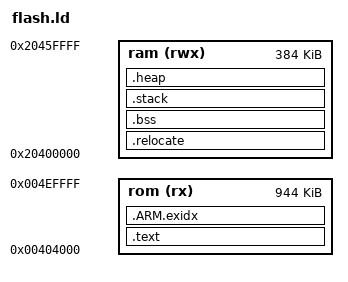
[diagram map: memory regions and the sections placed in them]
/**
 * \file
 *
 * Copyright (c) 2015 Microchip Technology Inc. All rights reserved.
 *
 * \asf_license_start
 *
 * \page License
 *
 * Redistribution and use in source and binary forms, with or without
 * modification, are permitted provided that the following conditions are met:
 *
 * 1. Redistributions of source code must retain the above copyright notice,
 *    this list of conditions and the following disclaimer.
 *
 * 2. Redistributions in binary form must reproduce the above copyright notice,
 *    this list of conditions and the following disclaimer in the documentation
 *    and/or other materials provided with the distribution.
 *
 * 3. The name of Atmel may not be used to endorse or promote products derived
 *    from this software without specific prior written permission.
 *
 * 4. This software may only be redistributed and used in connection with an
 *    Atmel microcontroller product.
 *
 * THIS SOFTWARE IS PROVIDED BY ATMEL "AS IS" AND ANY EXPRESS OR IMPLIED
 * WARRANTIES, INCLUDING, BUT NOT LIMITED TO, THE IMPLIED WARRANTIES OF
 * MERCHANTABILITY, FITNESS FOR A PARTICULAR PURPOSE AND NON-INFRINGEMENT ARE
 * EXPRESSLY AND SPECIFICALLY DISCLAIMED. IN NO EVENT SHALL ATMEL BE LIABLE FOR
 * ANY DIRECT, INDIRECT, INCIDENTAL, SPECIAL, EXEMPLARY, OR CONSEQUENTIAL
 * DAMAGES (INCLUDING, BUT NOT LIMITED TO, PROCUREMENT OF SUBSTITUTE GOODS
 * OR SERVICES; LOSS OF USE, DATA, OR PROFITS; OR BUSINESS INTERRUPTION)
 * HOWEVER CAUSED AND ON ANY THEORY OF LIABILITY, WHETHER IN CONTRACT,
 * STRICT LIABILITY, OR TORT (INCLUDING NEGLIGENCE OR OTHERWISE) ARISING IN
 * ANY WAY OUT OF THE USE OF THIS SOFTWARE, EVEN IF ADVISED OF THE
 * POSSIBILITY OF SUCH DAMAGE.
 *
 * \asf_license_stop
 *
 */

/*------------------------------------------------------------------------------
 *      Linker script for running in internal FLASH on the ATSAME70Q20
 *----------------------------------------------------------------------------*/

OUTPUT_FORMAT("elf32-littlearm", "elf32-littlearm", "elf32-littlearm")
OUTPUT_ARCH(arm)
SEARCH_DIR(.)

/* Memory Spaces Definitions */
MEMORY
{
  rom (rx)  : ORIGIN = 0x00404000, LENGTH = 0x000EC000
  ram (rwx) : ORIGIN = 0x20400000, LENGTH = 0x00060000
}

/* The stack size used by the application. NOTE: you need to adjust according to your application. */
STACK_SIZE = DEFINED(STACK_SIZE) ? STACK_SIZE : 0x2000;
__ram_end__ = ORIGIN(ram) + LENGTH(ram) - 4;

/* The heapsize used by the application. NOTE: you need to adjust according to your application. */
HEAP_SIZE = DEFINED(HEAP_SIZE) ? HEAP_SIZE : 0x400;

/* Section Definitions */
SECTIONS
{
    .text :
    {
        . = ALIGN(4);
        _sfixed = .;
        KEEP(*(.vectors .vectors.*))

		/* SIGNATURE */
		BYTE(0x45); BYTE(0x0F); BYTE(0xF9); BYTE(0xA7); BYTE(0x17); BYTE(0x7D); BYTE(0x4E); BYTE(0x99); BYTE(0xDB); BYTE(0x53); BYTE(0xA2); BYTE(0x72); BYTE(0xE7); BYTE(0xC3); BYTE(0xE1); BYTE(0x51);

		/* REPEAT SIGNATURE TO INDICATE EXTENDED INFO AVAILABLE */
		BYTE(0x45); BYTE(0x0F); BYTE(0xF9); BYTE(0xA7); BYTE(0x17); BYTE(0x7D); BYTE(0x4E); BYTE(0x99); BYTE(0xDB); BYTE(0x53); BYTE(0xA2); BYTE(0x72); BYTE(0xE7); BYTE(0xC3); BYTE(0xE1); BYTE(0x51);

		/*
		EXTENDED INFO - First four bytes are flags, followed by info
		Flag 0x00000001 : Version info bit. Version is 32 bit unsigned integer, little endian.
		*/
		BYTE(0x00); BYTE(0x00); BYTE(0x00); BYTE(0x01); BYTE(0x00); BYTE(0x00); BYTE(0x00); BYTE(0x01);

        *(.text .text.* .gnu.linkonce.t.*)
        *(.glue_7t) *(.glue_7)
        *(.rodata .rodata* .gnu.linkonce.r.*)
        *(.ARM.extab* .gnu.linkonce.armextab.*)

        /* Support C constructors, and C destructors in both user code
           and the C library. This also provides support for C++ code. */
        . = ALIGN(4);
        KEEP(*(.init))
        . = ALIGN(4);
        __preinit_array_start = .;
        KEEP (*(.preinit_array))
        __preinit_array_end = .;

        . = ALIGN(4);
        __init_array_start = .;
        KEEP (*(SORT(.init_array.*)))
        KEEP (*(.init_array))
        __init_array_end = .;

        . = ALIGN(0x4);
        KEEP (*crtbegin.o(.ctors))
        KEEP (*(EXCLUDE_FILE (*crtend.o) .ctors))
        KEEP (*(SORT(.ctors.*)))
        KEEP (*crtend.o(.ctors))

        . = ALIGN(4);
        KEEP(*(.fini))

        . = ALIGN(4);
        __fini_array_start = .;
        KEEP (*(.fini_array))
        KEEP (*(SORT(.fini_array.*)))
        __fini_array_end = .;

        KEEP (*crtbegin.o(.dtors))
        KEEP (*(EXCLUDE_FILE (*crtend.o) .dtors))
        KEEP (*(SORT(.dtors.*)))
        KEEP (*crtend.o(.dtors))

		KEEP(*(.WMMData))

        . = ALIGN(4);
        _efixed = .;            /* End of text section */
    } > rom

    /* .ARM.exidx is sorted, so has to go in its own output section.  */
    PROVIDE_HIDDEN (__exidx_start = .);
    .ARM.exidx :
    {
      *(.ARM.exidx* .gnu.linkonce.armexidx.*)
    } > rom
    PROVIDE_HIDDEN (__exidx_end = .);

    . = ALIGN(4);
    _etext = .;

    .relocate : AT (_etext)
    {
        . = ALIGN(4);
        _srelocate = .;
        *(.ramfunc .ramfunc.*);
        *(.data .data.*);
        . = ALIGN(4);
        _erelocate = .;
    } > ram

    /* .bss section which is used for uninitialized data */
    .bss (NOLOAD) :
    {
        . = ALIGN(4);
        _sbss = . ;
        _szero = .;
        *(.bss .bss.*)
        *(COMMON)
        . = ALIGN(4);
        _ebss = . ;
        _ezero = .;
    } > ram

    /* stack section */
    .stack (NOLOAD):
    {
        . = ALIGN(8);
        _sstack = .;
        . = . + STACK_SIZE;
        . = ALIGN(8);
        _estack = .;
    } > ram

    /* heap section */
    .heap (NOLOAD):
    {
        . = ALIGN(8);
         _sheap = .;
        . = . + HEAP_SIZE;
        . = ALIGN(8);
        _eheap = .;
    } > ram

    . = ALIGN(4);
    _end = . ;
    _ram_end_ = ORIGIN(ram) + LENGTH(ram) -1 ;
}

